VERSION ""

NS_ :

BS_:

BU_: XXX

BO_ 85 CID_WSCDOE: 8 XXX
 SG_ sig_rwunlm : 40|1@1+ (1,0) [0|1] "" XXX
 SG_ sig_waixqt : 56|8@1+ (1,0) [0|255] "" XXX

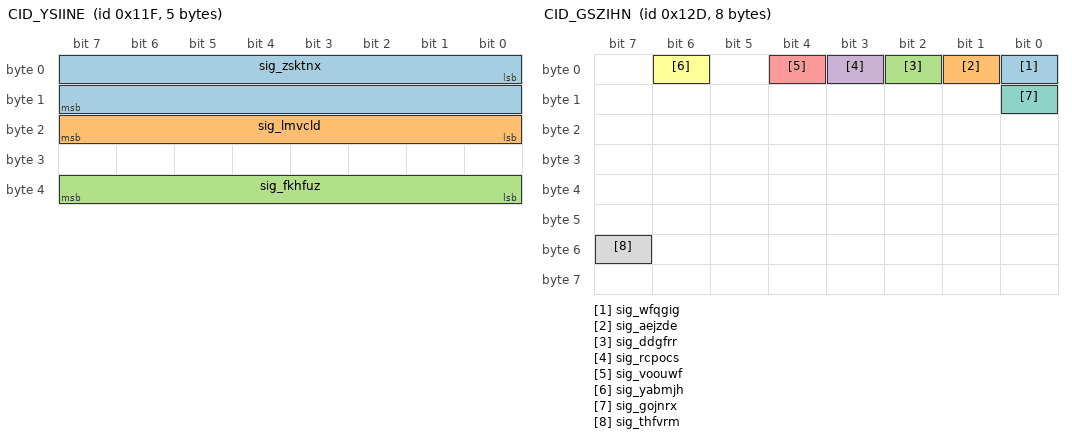
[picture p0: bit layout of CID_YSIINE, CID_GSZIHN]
BO_ 287 CID_YSIINE: 5 XXX
 SG_ sig_zsktnx : 0|16@1- (0.1,0) [-450|450] "" XXX
 SG_ sig_lmvcld : 16|8@1+ (4,0) [0|1020] "" XXX
 SG_ sig_fkhfuz : 32|8@1+ (1,0) [0|255] "" XXX

BO_ 289 CID_QLLKPY: 8 XXX
 SG_ sig_lgnptf : 0|12@1+ (1,0) [0|255] "" XXX

BO_ 301 CID_GSZIHN: 8 XXX
 SG_ sig_wfqgig : 0|1@0+ (1,0) [0|1] "" XXX
 SG_ sig_aejzde : 1|1@0+ (1,0) [0|1] "" XXX
 SG_ sig_ddgfrr : 2|1@0+ (1,0) [0|1] "" XXX
 SG_ sig_rcpocs : 3|1@0+ (1,0) [0|1] "" XXX
 SG_ sig_voouwf : 4|1@0+ (1,0) [0|1] "" XXX
 SG_ sig_yabmjh : 6|1@0+ (1,0) [0|1] "" XXX
 SG_ sig_gojnrx : 8|1@0+ (1,0) [0|1] "" XXX
 SG_ sig_thfvrm : 55|1@0+ (1,0) [0|1] "" XXX

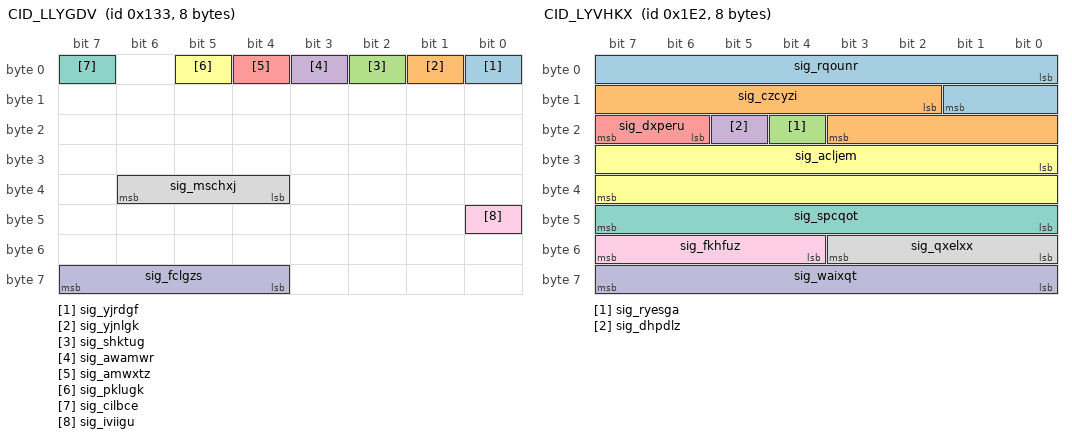
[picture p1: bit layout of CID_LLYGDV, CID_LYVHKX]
BO_ 307 CID_LLYGDV: 8 XXX
 SG_ sig_yjrdgf : 0|1@0+ (1,0) [0|1] "" XXX
 SG_ sig_yjnlgk : 1|1@1+ (1,0) [0|1] "" XXX
 SG_ sig_shktug : 2|1@1+ (1,0) [0|1] "" XXX
 SG_ sig_awamwr : 3|1@1+ (1,0) [0|1] "" XXX
 SG_ sig_amwxtz : 4|1@0+ (1,0) [0|1] "" XXX
 SG_ sig_pklugk : 5|1@0+ (1,0) [0|1] "" XXX
 SG_ sig_cilbce : 7|1@0+ (1,0) [0|1] "" XXX
 SG_ sig_mschxj : 36|3@1+ (1,0) [0|7] "" XXX
 SG_ sig_iviigu : 40|1@0+ (1,0) [0|1] "" XXX
 SG_ sig_fclgzs : 63|4@0+ (1,0) [0|15] "" XXX

BO_ 482 CID_LYVHKX: 8 XXX
 SG_ sig_rqounr : 0|10@1- (0.01,0) [0|5] "" XXX
 SG_ sig_czcyzi : 10|10@1- (0.01,0) [-5|0] "" XXX
 SG_ sig_ryesga : 20|1@0+ (1,0) [0|1] "" XXX
 SG_ sig_dhpdlz : 21|1@0+ (1,0) [0|1] "" XXX
 SG_ sig_dxperu : 22|2@1+ (1,0) [0|1] "" XXX
 SG_ sig_acljem : 24|16@1- (0.1,0) [-780|779.9] "" XXX
 SG_ sig_spcqot : 47|8@0+ (1,0) [0|255] "" XXX
 SG_ sig_qxelxx : 48|4@1+ (1,0) [0|15] "" XXX
 SG_ sig_fkhfuz : 52|4@1+ (1,0) [0|15] "" XXX
 SG_ sig_waixqt : 56|8@1+ (1,0) [0|255] "" XXX

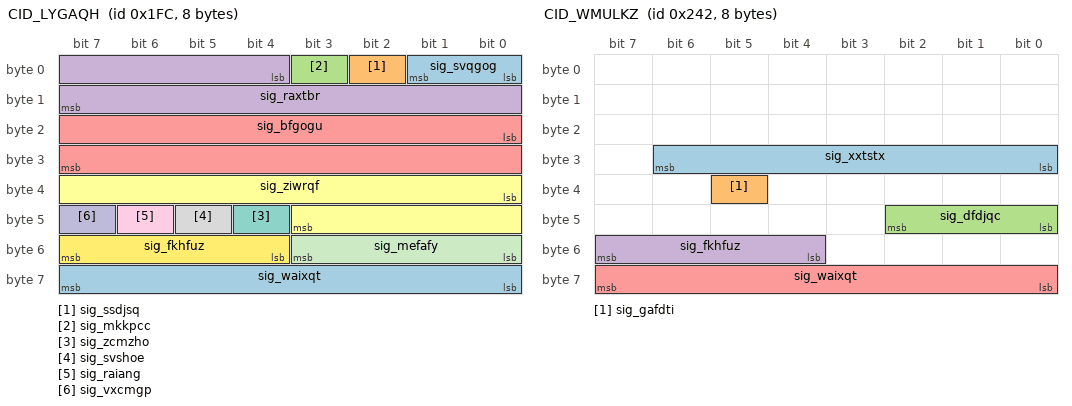
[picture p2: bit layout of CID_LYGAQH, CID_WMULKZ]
BO_ 508 CID_LYGAQH: 8 XXX
 SG_ sig_svqgog : 0|2@1+ (1,0) [0|1] "" XXX
 SG_ sig_ssdjsq : 2|1@1+ (1,0) [0|1] "" XXX
 SG_ sig_mkkpcc : 3|1@0+ (1,0) [0|1] "" XXX
 SG_ sig_raxtbr : 4|12@1- (1,0) [-2048|2047] "" XXX
 SG_ sig_bfgogu : 16|16@1- (0.1,0) [-780|779.9] "Deg" XXX
 SG_ sig_ziwrqf : 32|12@1- (0.01,0) [0|63] "" XXX
 SG_ sig_zcmzho : 44|1@0+ (1,0) [0|1] "" XXX
 SG_ sig_svshoe : 45|1@1+ (1,0) [0|255] "" XXX
 SG_ sig_raiang : 46|1@1+ (1,0) [0|1] "" XXX
 SG_ sig_vxcmgp : 47|1@0+ (1,0) [0|3] "" XXX
 SG_ sig_mefafy : 48|4@1+ (1,0) [0|15] "" XXX
 SG_ sig_fkhfuz : 52|4@1+ (1,0) [0|15] "" XXX
 SG_ sig_waixqt : 56|8@1+ (1,0) [0|255] "" XXX

BO_ 578 CID_WMULKZ: 8 XXX
 SG_ sig_xxtstx : 30|7@0+ (1,0) [0|127] "" XXX
 SG_ sig_gafdti : 37|1@0+ (1,0) [0|1] "" XXX
 SG_ sig_dfdjqc : 40|3@1+ (1,0) [0|7] "" XXX
 SG_ sig_fkhfuz : 55|4@0+ (1,0) [0|15] "" XXX
 SG_ sig_waixqt : 56|8@1+ (1,0) [0|255] "" XXX

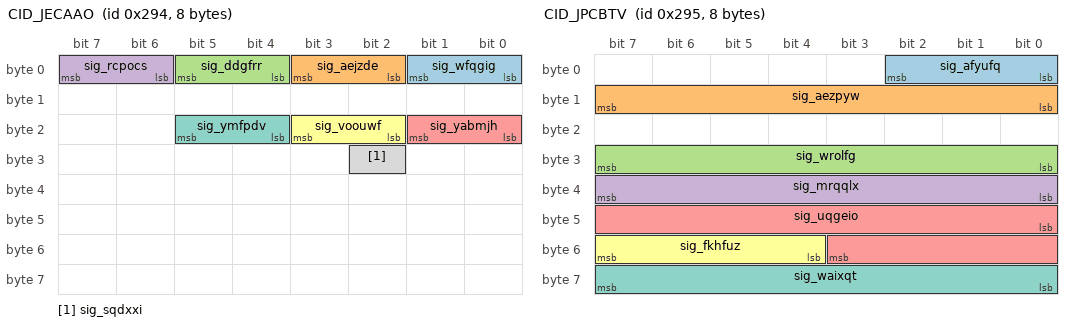
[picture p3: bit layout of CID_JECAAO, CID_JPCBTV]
BO_ 660 CID_JECAAO: 8 XXX
 SG_ sig_wfqgig : 1|2@0+ (1,0) [0|3] "" XXX
 SG_ sig_aejzde : 3|2@0+ (1,0) [0|3] "" XXX
 SG_ sig_ddgfrr : 5|2@0+ (1,0) [0|3] "" XXX
 SG_ sig_rcpocs : 7|2@0+ (1,0) [0|3] "" XXX
 SG_ sig_yabmjh : 17|2@0+ (1,0) [0|3] "" XXX
 SG_ sig_voouwf : 19|2@0+ (1,0) [0|3] "" XXX
 SG_ sig_ymfpdv : 21|2@0+ (1,0) [0|3] "" XXX
 SG_ sig_sqdxxi : 26|1@0+ (1,0) [0|1] "" XXX

BO_ 661 CID_JPCBTV: 8 XXX
 SG_ sig_afyufq : 2|3@0+ (1,0) [0|7] "" XXX
 SG_ sig_aezpyw : 15|8@0+ (1,0) [0|255] "" XXX
 SG_ sig_wrolfg : 31|8@0+ (1,0) [0|255] "" XXX
 SG_ sig_mrqqlx : 32|8@1+ (1,0) [0|255] "" XXX
 SG_ sig_uqgeio : 40|12@1+ (1,0) [0|255] "" XXX
 SG_ sig_fkhfuz : 52|4@1+ (1,0) [0|15] "" XXX
 SG_ sig_waixqt : 63|8@0+ (1,0) [0|255] "" XXX

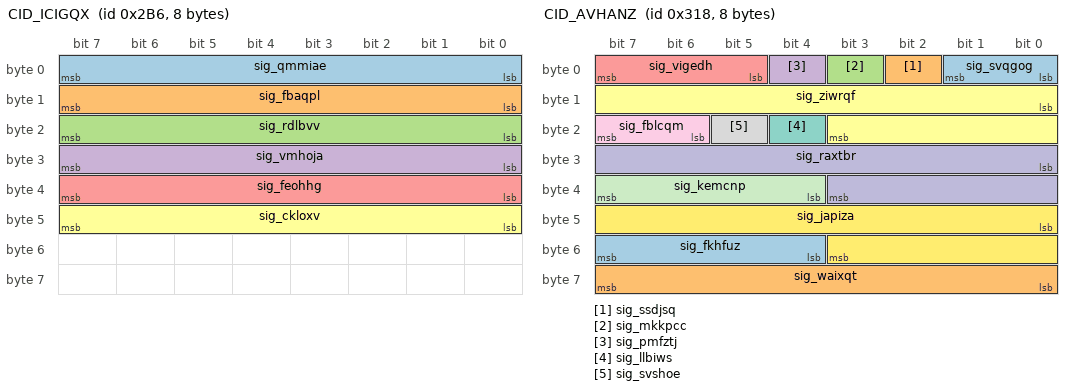
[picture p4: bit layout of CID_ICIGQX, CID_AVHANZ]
BO_ 694 CID_ICIGQX: 8 XXX
 SG_ sig_qmmiae : 7|8@0+ (1,0) [0|255] "" XXX
 SG_ sig_fbaqpl : 15|8@0+ (1,0) [0|255] "" XXX
 SG_ sig_rdlbvv : 23|8@0+ (1,0) [0|255] "" XXX
 SG_ sig_vmhoja : 31|8@0+ (1,0) [0|255] "" XXX
 SG_ sig_feohhg : 39|8@0+ (1,0) [0|255] "" XXX
 SG_ sig_ckloxv : 47|8@0+ (1,0) [0|255] "" XXX

BO_ 790 CID_CKFVKC: 8 XXX
 SG_ sig_blhzkt : 3|4@0+ (1,0) [0|1] "" XXX
 SG_ sig_xncfwm : 4|2@1+ (1,0) [0|3] "" XXX
 SG_ sig_jpejsb : 6|2@1+ (1,0) [0|3] "" XXX
 SG_ sig_hnvcoz : 8|2@1+ (1,0) [0|3] "" XXX
 SG_ sig_rwxpii : 10|1@1+ (1,0) [0|1] "" XXX
 SG_ sig_dgabuz : 11|4@1+ (1,0) [0|1] "" XXX
 SG_ sig_dhzbjn : 15|1@0+ (1,0) [0|1] "" XXX
 SG_ sig_acljem : 16|11@1- (1,0) [-1024|1023] "" XXX
 SG_ sig_ryesga : 27|1@1+ (1,0) [0|1] "" XXX
 SG_ sig_dhpdlz : 28|1@1+ (1,0) [0|3] "" XXX
 SG_ sig_mtvear : 29|1@0+ (1,0) [0|1] "" XXX
 SG_ sig_iqnige : 30|1@0+ (1,0) [0|1] "" XXX
 SG_ sig_veewby : 31|1@0+ (1,0) [0|1] "" XXX
 SG_ sig_svxlkf : 32|2@1+ (1,0) [0|3] "" XXX
 SG_ sig_ewlilf : 34|2@1+ (1,0) [0|3] "" XXX
 SG_ sig_nqnxwq : 36|4@1+ (1,0) [0|3] "" XXX
 SG_ sig_rswabp : 40|8@1+ (5,-5) [-5|1270] "" XXX
 SG_ sig_emcfnl : 49|2@0+ (1,0) [0|3] "" XXX
 SG_ sig_ylmsdh : 51|2@0+ (1,0) [0|3] "" XXX
 SG_ sig_fkhfuz : 52|4@1+ (1,0) [0|15] "" XXX
 SG_ sig_waixqt : 56|8@1+ (1,0) [0|15] "" XXX

BO_ 792 CID_AVHANZ: 8 XXX
 SG_ sig_svqgog : 0|2@1+ (1,0) [0|1] "" XXX
 SG_ sig_ssdjsq : 2|1@1+ (1,0) [0|1] "" XXX
 SG_ sig_mkkpcc : 3|1@1+ (1,0) [0|1] "" XXX
 SG_ sig_pmfztj : 4|1@1+ (1,0) [0|1] "" XXX
 SG_ sig_vigedh : 5|3@1+ (1,0) [0|1] "" XXX
 SG_ sig_ziwrqf : 8|12@1- (1,0) [-2048|2047] "" XXX
 SG_ sig_llbiws : 20|1@1+ (1,0) [0|1] "" XXX
 SG_ sig_svshoe : 21|1@1+ (1,0) [0|1] "" XXX
 SG_ sig_fblcqm : 22|2@1+ (1,0) [0|15] "" XXX
 SG_ sig_raxtbr : 24|12@1- (1,0) [-2048|2047] "" XXX
 SG_ sig_kemcnp : 36|4@1+ (1,0) [0|15] "" XXX
 SG_ sig_japiza : 40|12@1+ (1,0) [0|4095] "" XXX
 SG_ sig_fkhfuz : 52|4@1+ (1,0) [0|15] "" XXX
 SG_ sig_waixqt : 56|8@1+ (1,0) [0|255] "" XXX

BO_ 813 CID_RZVTOX: 8 XXX
 SG_ sig_zvrrzq : 0|9@1+ (0.5,0) [0|255.5] "" XXX
 SG_ sig_jsuvij : 9|1@1+ (1,0) [0|1] "" XXX
 SG_ sig_lpxwvx : 10|3@1+ (1,0) [0|7] "" XXX
 SG_ sig_hxibve : 13|3@1+ (1,0) [0|7] "" XXX
 SG_ sig_qhfxsv : 16|1@1+ (1,0) [0|1] "" XXX
 SG_ sig_tbigjb : 17|1@1+ (1,0) [0|1] "" XXX
 SG_ sig_mkkpcc : 18|1@1+ (1,0) [0|1] "" XXX
 SG_ sig_nglvqc : 19|3@1+ (1,0) [0|1] "" XXX
 SG_ sig_yghuhi : 22|1@0+ (1,0) [0|1] "" XXX
 SG_ sig_ezxxoj : 23|1@0+ (1,0) [0|1] "" XXX
 SG_ sig_hnvcoz : 24|1@1+ (1,0) [0|1] "" XXX
 SG_ sig_dplmsn : 25|7@1+ (1,0) [0|127] "" XXX
 SG_ sig_qavxnu : 32|4@1+ (1,0) [0|15] "" XXX
 SG_ sig_uakuch : 36|12@1+ (1,0) [0|4095] "" XXX
 SG_ sig_fkhfuz : 48|4@1+ (1,0) [0|15] "" XXX
 SG_ sig_qmxals : 55|4@0+ (1,0) [0|15] "" XXX
 SG_ sig_waixqt : 56|8@1+ (1,0) [0|255] "" XXX

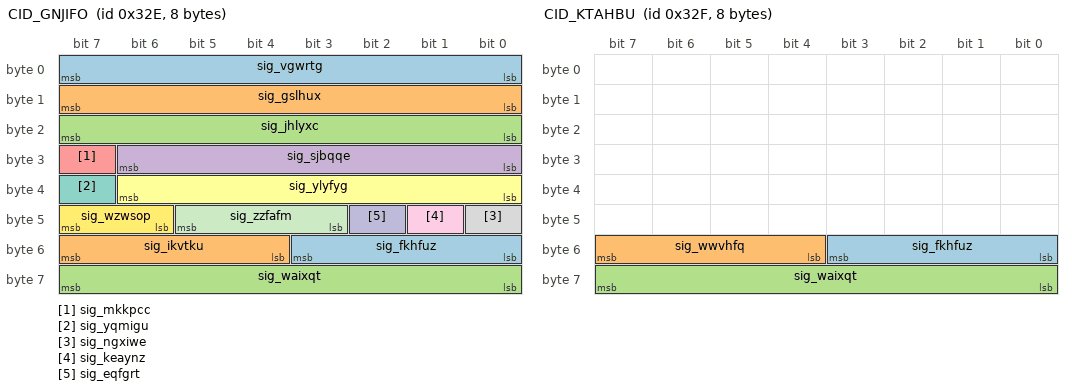
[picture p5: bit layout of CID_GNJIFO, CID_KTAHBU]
BO_ 814 CID_GNJIFO: 8 XXX
 SG_ sig_vgwrtg : 0|8@1+ (0.05,-5) [-100|155] "" XXX
 SG_ sig_gslhux : 8|8@1+ (0.05,-5) [0|1.26] "" XXX
 SG_ sig_jhlyxc : 16|8@1+ (0.05,-5) [0|1.26] "" XXX
 SG_ sig_sjbqqe : 24|7@1+ (0.2,0) [0|12.7] "" XXX
 SG_ sig_mkkpcc : 31|1@0+ (1,0) [0|1] "" XXX
 SG_ sig_ylyfyg : 32|7@1+ (0.2,-16) [0|12.7] "" XXX
 SG_ sig_yqmigu : 39|1@0+ (1,0) [0|1] "" XXX
 SG_ sig_ngxiwe : 40|1@0+ (1,0) [0|1] "" XXX
 SG_ sig_keaynz : 41|1@0+ (1,0) [0|1] "" XXX
 SG_ sig_eqfgrt : 42|1@1+ (1,0) [0|3] "" XXX
 SG_ sig_zzfafm : 45|3@0+ (1,0) [0|1] "" XXX
 SG_ sig_wzwsop : 46|2@1+ (1,0) [0|3] "" XXX
 SG_ sig_fkhfuz : 48|4@1+ (1,0) [0|15] "" XXX
 SG_ sig_ikvtku : 55|4@0+ (1,0) [0|15] "" XXX
 SG_ sig_waixqt : 56|8@1+ (1,0) [0|255] "" XXX

BO_ 815 CID_KTAHBU: 8 XXX
 SG_ sig_fkhfuz : 48|4@1+ (1,0) [0|15] "" XXX
 SG_ sig_wwvhfq : 55|4@0+ (1,0) [0|15] "" XXX
 SG_ sig_waixqt : 56|8@1+ (1,0) [0|255] "" XXX

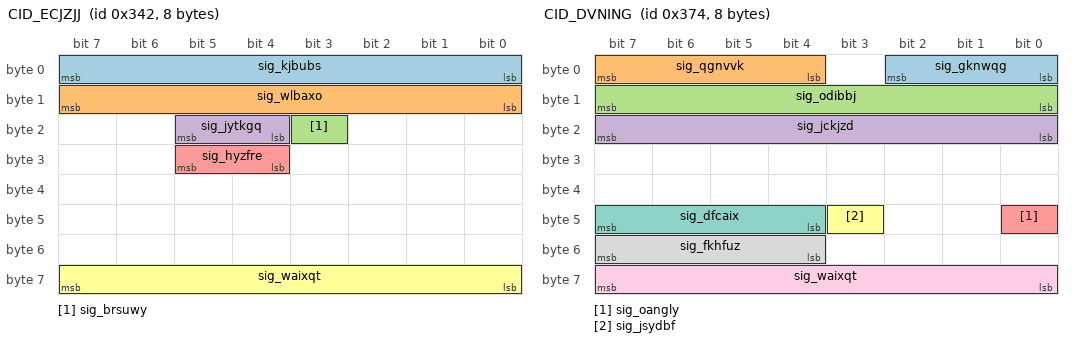
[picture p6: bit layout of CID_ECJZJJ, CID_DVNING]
BO_ 834 CID_ECJZJJ: 8 XXX
 SG_ sig_kjbubs : 0|8@1+ (0.01,0) [0|2.55] "" XXX
 SG_ sig_wlbaxo : 8|8@1+ (0.01,0) [0|2.55] "" XXX
 SG_ sig_brsuwy : 19|1@1+ (1,0) [0|1] "" XXX
 SG_ sig_jytkgq : 20|2@1+ (1,0) [0|255] "" XXX
 SG_ sig_hyzfre : 28|2@1+ (1,0) [0|1] "" XXX
 SG_ sig_waixqt : 56|8@1+ (1,0) [0|255] "" XXX

 BO_ 884 CID_DVNING: 8 MRR
 SG_ sig_gknwqg : 2|3@0+ (1,0) [0|3] "" MRR
 SG_ sig_qgnvvk : 7|4@0+ (1,0) [0|15] "" MRR
 SG_ sig_odibbj : 15|8@0+ (0.1,-12) [0|255] "" MRR
 SG_ sig_jckjzd : 23|8@0+ (1,-100) [0|255] "" MRR
 SG_ sig_oangly : 40|1@0+ (1,0) [0|3] "" MRR
 SG_ sig_jsydbf : 43|1@0+ (1,0) [0|1] "" XXX
 SG_ sig_dfcaix : 44|4@1+ (1,0) [0|15] "" XXX
 SG_ sig_fkhfuz : 52|4@1+ (1,0) [0|15] "" MRR
 SG_ sig_waixqt : 56|8@1+ (1,0) [0|255] "" MRR

BO_ 944 CID_BPDGFH: 8 XXX
 SG_ sig_yqnydy : 1|2@0+ (1,0) [0|3] "" XXX
 SG_ sig_bxlcyr : 2|1@0+ (1,0) [0|1] "" XXX
 SG_ sig_pbnynq : 4|2@0+ (1,0) [0|3] "" XXX
 SG_ sig_trmxke : 5|1@0+ (1,0) [0|1] "" XXX
 SG_ sig_gxxhjn : 6|1@0+ (1,0) [0|1] "" XXX
 SG_ sig_ajimyq : 7|1@0+ (1,0) [0|1] "" XXX
 SG_ sig_sdqkos : 8|1@0+ (1,0) [0|1] "" XXX
 SG_ sig_fxxgwq : 11|3@0+ (1,0) [0|7] "" XXX
 SG_ sig_bohbqo : 12|1@0+ (1,0) [0|1] "" XXX
 SG_ sig_kfqrly : 14|2@0+ (1,0) [0|3] "" XXX
 SG_ sig_uomncs : 15|1@0+ (1,0) [0|1] "" XXX
 SG_ sig_zbwjzs : 16|1@0+ (1,0) [0|1] "" XXX
 SG_ sig_zndlfc : 18|2@0+ (1,0) [0|3] "" XXX
 SG_ sig_skgpdn : 19|1@0+ (1,0) [0|1] "" XXX
 SG_ sig_cbkuwq : 23|4@0+ (1,0) [0|15] "" XXX
 SG_ sig_ntsbuw : 24|28@1+ (1,0) [0|268435455] "" XXX
 SG_ sig_fkhfuz : 52|4@1+ (1,0) [0|15] "" XXX
 SG_ sig_waixqt : 56|8@1+ (1,0) [0|255] "" XXX

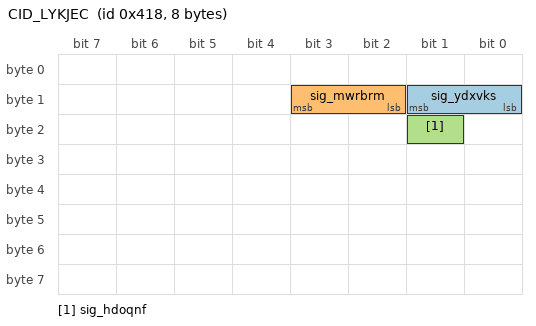
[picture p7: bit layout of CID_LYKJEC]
BO_ 1048 CID_LYKJEC: 8 XXX
 SG_ sig_ydxvks : 9|2@0+ (1,0) [0|1] "" XXX
 SG_ sig_mwrbrm : 11|2@0+ (1,0) [0|1] "" XXX
 SG_ sig_hdoqnf : 17|1@0+ (1,0) [0|1] "" XXX

VAL_ 578 sig_dfdjqc 4 "D" 2 "R" 3 "N" 1 "P";
VAL_ 790 sig_blhzkt 11 "AutoFullBeamActive" 2 "AutoFullBeamInactive";
VAL_ 790 sig_xncfwm 0 "GRAY" 1 "GREEN" 2 "YELLOW" 3 "RED";
VAL_ 790 sig_jpejsb 3 "ALARM_AND_LKA" 2 "LKA" 1 "ALARM" 0 "DISABLE";
VAL_ 790 sig_ewlilf 0 "GRAY" 1 "GREEN" 2 "YELLOW" 3 "RED";
VAL_ 790 sig_emcfnl 0 "VIBRATION" 1 "AUDIO" 2 "AUDIO_AND_VIBRATION";
VAL_ 792 sig_svqgog 0 "NotReady" 1 "Ready" 2 "Active" 3 "TemporaryFail";
VAL_ 813 sig_lpxwvx 4 "4BAR" 3 "3BAR" 2 "2BAR" 1 "1BAR";
VAL_ 813 sig_nglvqc 0 "OFF" 2 "ACC_ON" 3 "ACC_ACTIVE" 5 "FORCE_ACCEL" 7 "ERROR";
VAL_ 813 sig_dplmsn 36 "ACC_ERROR" 22 "OVERRIDE" 12 "ENGAGE" 8 "DISENGAGE" 20 "ACC_ON" 32 "ACC_OFF" 48 "CHECK_GEAR_D" 16 "FORCE_ACCEL" 0 "NONE";
VAL_ 814 sig_zzfafm 0 "Off" 1 "Passive" 2 "StandBy" 3 "ActiveControl" 4 "BrakeOnly" 5 "Override" 6 "Standstill" 7 "Failure";
VAL_ 814 sig_wzwsop 0 "Softoff" 1 "Fastoff" 2 "Immediateoff" 3 "Initial";
VAL_ 834 sig_jytkgq 2 "SPORT" 1 "ECO" 0 "SNOW";
VAL_ 834 sig_hyzfre 3 "HEV" 2 "FORCE_EV" 1 "EV";
VAL_ 944 sig_pbnynq 0 "NOTPRESSED" 1 "DOWN_SETSPEED" 3 "UP_RESETSPEED";
